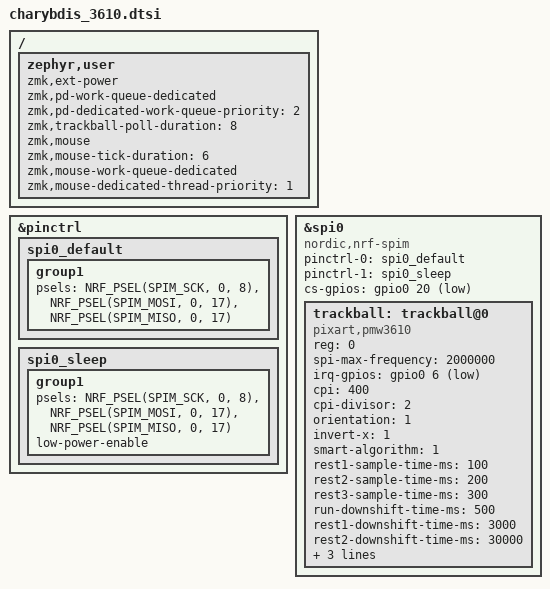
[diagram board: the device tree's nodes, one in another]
/ {
    zephyr,user {
        /* --- Power and work queue settings --- */
        zmk,ext-power;

        zmk,pd-work-queue-dedicated;
        zmk,pd-dedicated-work-queue-priority = <2>;
        zmk,trackball-poll-duration = <8>;

        zmk,mouse;
        zmk,mouse-tick-duration = <6>;
        zmk,mouse-work-queue-dedicated;
        zmk,mouse-dedicated-thread-priority = <1>;
    };
};

&pinctrl {
    spi0_default: spi0_default {
        group1 {
            psels = <NRF_PSEL(SPIM_SCK, 0, 8)>,
                    <NRF_PSEL(SPIM_MOSI, 0, 17)>,
                    <NRF_PSEL(SPIM_MISO, 0, 17)>;
        };
    };

    spi0_sleep: spi0_sleep {
        group1 {
            psels = <NRF_PSEL(SPIM_SCK, 0, 8)>,
                    <NRF_PSEL(SPIM_MOSI, 0, 17)>,
                    <NRF_PSEL(SPIM_MISO, 0, 17)>;
            low-power-enable;
        };
    };
};

&spi0 {
    status = "okay";
    compatible = "nordic,nrf-spim";
    pinctrl-0 = <&spi0_default>;
    pinctrl-1 = <&spi0_sleep>;
    pinctrl-names = "default", "sleep";
    cs-gpios = <&gpio0 20 GPIO_ACTIVE_LOW>;

    trackball: trackball@0 {
        status = "okay";
        compatible = "pixart,pmw3610";
        reg = <0>;
        spi-max-frequency = <2000000>;
        irq-gpios = <&gpio0 6 (GPIO_ACTIVE_LOW | GPIO_PULL_UP)>;

        /* --- Mouse speed & behavior --- */
        cpi = <400>;
        cpi-divisor = <2>;

        orientation = <1>;         // 0 = normal, 1 = 90° rotation
        invert-x = <1>;
        smart-algorithm = <1>;

        rest1-sample-time-ms = <100>;
        rest2-sample-time-ms = <200>;
        rest3-sample-time-ms = <300>;

        run-downshift-time-ms = <500>;
        rest1-downshift-time-ms = <3000>;
        rest2-downshift-time-ms = <30000>;

        /* --- Input mapping --- */
        evt-type = <1>;            // INPUT_EV_REL
        x-input-code = <0>;        // INPUT_REL_X
        y-input-code = <1>;        // INPUT_REL_Y
    };
};
